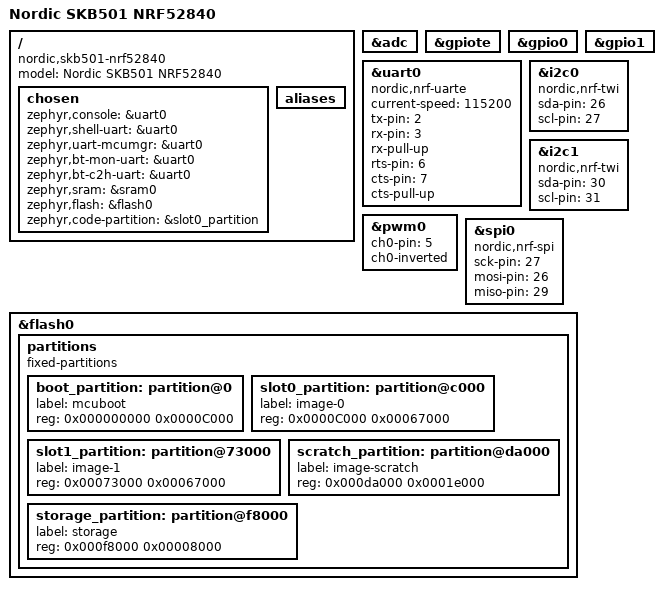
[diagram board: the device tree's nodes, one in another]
/*
 * Copyright (c) 2017 Linaro Limited
 *
 * SPDX-License-Identifier: Apache-2.0
 */

/dts-v1/;
#include <nordic/nrf52840_qiaa.dtsi>

/ {
	model = "Nordic SKB501 NRF52840";
	compatible = "nordic,skb501-nrf52840";

	chosen {
		zephyr,console = &uart0;
		zephyr,shell-uart = &uart0;
		zephyr,uart-mcumgr = &uart0;
		zephyr,bt-mon-uart = &uart0;
		zephyr,bt-c2h-uart = &uart0;
		zephyr,sram = &sram0;
		zephyr,flash = &flash0;
		zephyr,code-partition = &slot0_partition;
	};	

	/* These aliases are provided for compatibility with samples */
	aliases {
	};
};

&adc {
	status = "okay";
};

&gpiote {
	status = "okay";
};

&gpio0 {
	status = "okay";
};

&gpio1 {
	status = "okay";
};

&uart0 {
	compatible = "nordic,nrf-uarte";
	status = "okay";
	current-speed = <115200>;
	tx-pin = <2>;
	rx-pin = <3>;
	rx-pull-up;
	rts-pin = <6>;
	cts-pin = <7>;
	cts-pull-up;
};

&i2c0 {
	compatible = "nordic,nrf-twi";
	status = "okay";
	sda-pin = <26>;
	scl-pin = <27>;
};

&i2c1 {
	compatible = "nordic,nrf-twi";
	/* Cannot be used together with spi1. */
	/* status = "okay"; */
	sda-pin = <30>;
	scl-pin = <31>;
};

&pwm0 {
	status = "okay";
	ch0-pin = <5>;
	ch0-inverted;
};

&spi0 {
	compatible = "nordic,nrf-spi";
	/* Cannot be used together with i2c0. */
	/* status = "okay"; */
	sck-pin = <27>;
	mosi-pin = <26>;
	miso-pin = <29>;
};


&flash0 {

	partitions {
		compatible = "fixed-partitions";
		#address-cells = <1>;
		#size-cells = <1>;

		boot_partition: partition@0 {
			label = "mcuboot";
			reg = <0x000000000 0x0000C000>;
		};
		slot0_partition: partition@c000 {
			label = "image-0";
			reg = <0x0000C000 0x00067000>;
		};
		slot1_partition: partition@73000 {
			label = "image-1";
			reg = <0x00073000 0x00067000>;
		};
		scratch_partition: partition@da000 {
			label = "image-scratch";
			reg = <0x000da000 0x0001e000>;
		};

		/*
		 * The flash starting at 0x000f8000 and ending at
		 * 0x000fffff is reserved for use by the application.
		 */

		/*
		 * Storage partition will be used by FCB/LittleFS/NVS
		 * if enabled.
		 */
		storage_partition: partition@f8000 {
			label = "storage";
			reg = <0x000f8000 0x00008000>;
		};
	};
};
